# alb32r003x register map
Vendor: ALB; Series: ALB RT SoC
CPU: ALB XF, little endian
Registers are 32-bit, access not given, reset 0x0 unless marked. A register's access mark holds for its fields unless they carry their own. Offsets are from the block's base; [hi:lo] are bit positions.

## SPI1
Base 0x26000000
Same registers: SPI2 0x26001000, SPI3 0x26002000
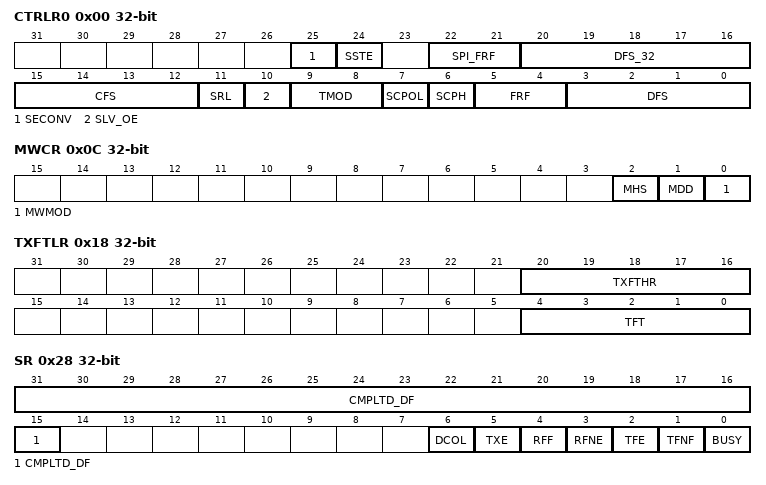
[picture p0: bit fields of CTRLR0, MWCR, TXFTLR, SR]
0x00 CTRLR0
  [25] SECONV — Set the Endianness for XIP and data register reads
  [24] SSTE — Target Select Toggle Enable.While operating in SPI mode with clock phase (SCPH) set to 0, this register
  [22:21] SPI_FRF — SPI Frame Format Selects data frame format for Transmitting/Receiving the data. Bits only valid when
  [20:16] DFS_32 — Data Frame Size in 32-bit transfer size mode. Used to select the data frame size in 32-bit transfer mode.Control
  [15:12] CFS — Control Frame Size. Selects the length of the control word for
  [11] SRL — Shift Register Loop.Used for testing purposes only. When internally active, connects the transmit shift
  [10] SLV_OE — Target Output Enable.Relevant only when the DWC_ssi is configured as a serial-target device. When configured
  [9:8] TMOD — Transfer Mode.
  [7] SCPOL — Serial Clock Polarity.Valid when the frame format (FRF) is set to Motorola SPI.
  [6] SCPH — Serial Clock Phase.Valid when the frame format (FRF) is set to Motorola SPI.
  [5:4] FRF — Frame Format.Selects which serial protocol transfers the data.
  [3:0] DFS — writing to this field will not have any effect.
0x04 CTRLR1
  [15:0] NDF — Number of Data Frames.
0x08 SSIENR
  [0] SSIC_EN — SSI Enable.
0x0C MWCR
  [2] MHS — Microwire Handshaking.
  [1] MDD — Microwire Control.
  [0] MWMOD — Microwire Transfer Mode.
0x10 SER
  [0] SER — Chip Select Enable Flag.
0x14 BAUDR
  [15:1] SCKDV — SSI Clock Divider.
0x18 TXFTLR
  [20:16] TXFTHR — Transfer start FIFO level.
  [4:0] TFT — Transmit FIFO Threshold.
0x1C RXFTLR
  [4:0] RFT — Receive FIFO Threshold.
0x20 TXFLR
  [5:0] TXTFL — Transmit FIFO Level.
0x24 RXFLR
  [5:0] RXTFL — Receive FIFO Level.
0x28 SR
  [31:15] CMPLTD_DF — Completed Data frames This field indicates total data frames transferred in the previous internal DMA
  [6] DCOL — Data Collision Error.
  [5] TXE — Transmission Error.
  [4] RFF — Receive FIFO Full.
  [3] RFNE — Receive FIFO Not Empty.
  [2] TFE — Transmit FIFO Empty.
  [1] TFNF — Transmit FIFO Not Full.
  [0] BUSY — SSI Busy Flag.
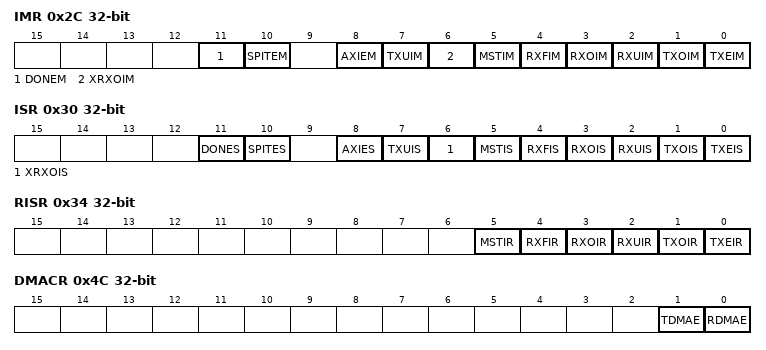
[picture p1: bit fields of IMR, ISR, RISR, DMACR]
0x2C IMR
  [11] DONEM — SSI Done Interrupt Mask
  [10] SPITEM — SPI Transmit Error Interrupt Mask
  [8] AXIEM — AXI Error Interrupt Mask
  [7] TXUIM — Transmit FIFO Underflow Interrupt Mask
  [6] XRXOIM — XIP Receive FIFO Overflow Interrupt Mask
  [5] MSTIM — Multi-Controller Contention Interrupt Mask. This bit field is not present if the DWC_ssi is configured
  [4] RXFIM — Receive FIFO Full Interrupt Mask 0 - ssi_rxf_intr interrupt is masked 1 - ssi_rxf_intr interrupt is not
  [3] RXOIM — Receive FIFO Overflow Interrupt Mask
  [2] RXUIM — Receive FIFO Underflow Interrupt Mask
  [1] TXOIM — Transmit FIFO Overflow Interrupt Mask
  [0] TXEIM — Transmit FIFO Empty Interrupt Mask
0x30 ISR
  [11] DONES — SSI Done Interrupt Status
  [10] SPITES — SPI Transmit Error Interrupt
  [8] AXIES — AXI Error Interrupt Status
  [7] TXUIS — Transmit FIFO Underflow Interrupt Status
  [6] XRXOIS — XIP Receive FIFO Overflow Interrupt Status
  [5] MSTIS — Multi-Controller Contention Interrupt Status. This bit field is not present if the DWC_ssi is configured
  [4] RXFIS — Receive FIFO Full Interrupt Status
  [3] RXOIS — Receive FIFO Overflow Interrupt StatuS
  [2] RXUIS — Receive FIFO Underflow Interrupt Status
  [1] TXOIS — Transmit FIFO Overflow Interrupt Status
  [0] TXEIS — Transmit FIFO Empty Interrupt Status
0x34 RISR
  [5] MSTIR — Multi-Controller Contention Interrupt Status. This bit field is not present if the DWC_ssi is configured
  [4] RXFIR — Receive FIFO Full Interrupt Status
  [3] RXOIR — Receive FIFO Overflow Interrupt StatuS
  [2] RXUIR — Receive FIFO Underflow Interrupt Status
  [1] TXOIR — Transmit FIFO Overflow Interrupt Status
  [0] TXEIR — Transmit FIFO Empty Interrupt Status
0x38 TXOICR
  [0] TXOICR — Clear Transmit FIFO Overflow Interrupt.
0x3C RXOICR
  [0] RXOICR — Clear Receive FIFO Overflow Interrupt.
0x40 RXUICR
  [0] RXUICR — Clear Receive FIFO Underflow Interrupt.
0x44 MSTICR
  [0] RXOICR — Clear Multi-Controller Contention Interrupt.
0x48 ICR
  [0] ICR — Clear Interrupts.A read clears
0x4C DMACR
  [1] TDMAE — Transmit DMA Enable. This bit enables/disables the transmit FIFO DMA channel.
  [0] RDMAE — Receive DMA Enable. This bit enables/disables the receive FIFO DMA channel.
0x50 DMATDLR
  [4:0] DMATDL — Transmit Data Level. This bit field controls the level at which a DMA request is made by the transmit
0x54 DMARDLR
  [4:0] DMARDL — Receive Data Level. This bit field controls the level at which a DMA request is made by the receive logic.
0x58 IDR
  [31:0] IDCODE — Identification code.
0x5C SSI_VERSION_ID
  [31:0] SSI_VERSION_ID — Contains the hex representation of the Synopsys component version. Consists of ASCII value for each number
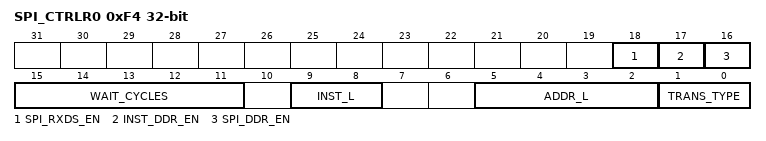
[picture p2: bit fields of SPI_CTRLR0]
0xF4 SPI_CTRLR0
  [18] SPI_RXDS_EN — Read data strobe enable bit. Once this bit is set to 1 DW_apb_ssi will use Read datastrobe (rxds) to
  [17] INST_DDR_EN — Instruction DDR Enable bit. This will enable Dual-data rate transfer for Instruction phase.
  [16] SPI_DDR_EN — SPI DDR Enable bit. This will enable Dual-data rate transfers in Enhanced SPI frame formats of SPI.
  [15:11] WAIT_CYCLES — Wait cycles in Enhanced SPI mode between control frames transmit and data reception. Specified as number
  [9:8] INST_L — Enhanced SPI mode instruction length in bits.
  [5:2] ADDR_L — This bit defines Length of Address to be transmitted. Only after this much bits are programmed in to
  [1:0] TRANS_TYPE — Address and instruction transfer format.
